# YT9215 register map
Vendor: Motorcomm; Series: YT921x; File version: 1.0
Registers are 32-bit, read-write, no defined reset value unless marked. A register's access mark holds for its fields unless they carry their own. Offsets are from the block's base; [hi:lo] are bit positions; lines under a group give offsets from that group; {n}, {i} and the like mark numbered series.

## PARSER — Ingress parser
Base 0x00210000
{0x0+4i} TPID_IGR[{i}] (i=0..3) — Four tag protocol identifier values the parser can recognise as a VLAN tag. PORT_IGR_TPID chooses which of them each port accepts. Index: n = 0 to 3.
  [15:0] TPID — Tag protocol identifier. An example is 0x8100.
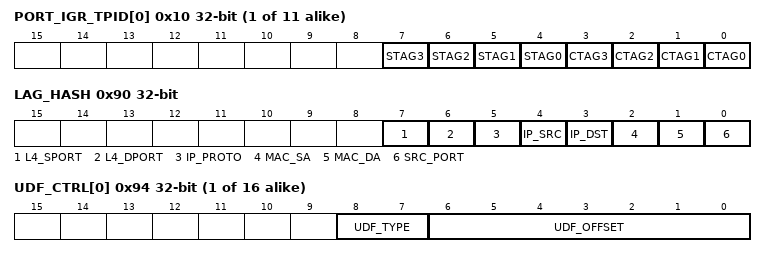
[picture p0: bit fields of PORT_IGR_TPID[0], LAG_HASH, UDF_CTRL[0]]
{0x10+4i} PORT_IGR_TPID[{i}] (i=0..10) — yt921x_vlan_aware_set writes the register to make a port VLAN-aware or VLAN-unaware. It is inferred from the names that the register chooses which TPID_IGR entries one port treats as a customer tag and which as a service tag. VLAN-aware and VLAN-unaware ports shows how this makes a port ignore VLAN tags. Index: port = 0 to 10.
  [n+4] STAG{n} (n=0..3) — It is inferred from the names that entry n of TPID_IGR marks a service tag on this port.
  [n] CTAG{n} (n=0..3) — It is inferred from the names that entry n of TPID_IGR marks a customer tag on this port.
0x90 LAG_HASH — Frame fields that feed the hash which spreads traffic over the members of a group.
  [7] L4_SPORT — Include the layer 4 source port.
  [6] L4_DPORT — Include the layer 4 destination port.
  [5] IP_PROTO — Include the IP protocol number.
  [4] IP_SRC — Include the IP source address.
  [3] IP_DST — Include the IP destination address.
  [2] MAC_SA — Include the source MAC address.
  [1] MAC_DA — Include the destination MAC address.
  [0] SRC_PORT — Include the receiving port.
{0x94+4i} UDF_CTRL[{i}] (i=0..15) — Position of one two-byte window that ACL keys of type UDF can match. Key type UDFk matches windows 2k and 2k + 1. Index: n = 0 to 15.
  [8:7] UDF_TYPE — Header the offset is counted from.
    0=L2 (Start of the Ethernet header); 1=L3 (Start of the layer 3 header); 2=L4 (Start of the layer 4 header)
  [6:0] UDF_OFFSET — Offset in bytes of the two-byte window from the start of that header.

## PORT_VLAN — Ingress port VLAN
Base 0x00230000
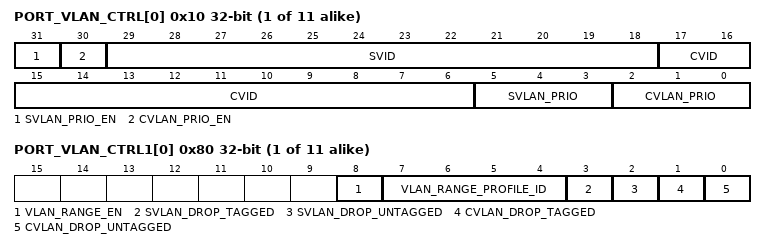
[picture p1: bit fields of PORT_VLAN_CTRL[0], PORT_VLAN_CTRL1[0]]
{0x10+4i} PORT_VLAN_CTRL[{i}] (i=0..10) — VLAN IDs and priorities given to frames that arrive on a port without the matching tag. Index: port = 0 to 10.
  [31] SVLAN_PRIO_EN — The Linux name reads as: use PORT_VLAN_CTRL.SVLAN_PRIO as the default service tag priority. The vendor SDK names the bit PRIORITY_TAG_SVID_EN, which reads as: give the default service VLAN ID to a priority-tagged frame. No code of either source uses the bit, and it is not known which reading is right.
  [30] CVLAN_PRIO_EN — The Linux name reads as: use PORT_VLAN_CTRL.CVLAN_PRIO as the default customer tag priority. The vendor SDK names the bit PRIORITY_TAG_CVID_EN, which reads as: give the default customer VLAN ID to a priority-tagged frame. No code of either source uses the bit, and it is not known which reading is right.
  [29:18] SVID — Default service VLAN ID.
  [17:6] CVID — Default customer VLAN ID (the port VLAN ID).
  [5:3] SVLAN_PRIO — Default service tag priority.
  [2:0] CVLAN_PRIO — Default customer tag priority.
{0x80+4i} PORT_VLAN_CTRL1[{i}] (i=0..10) — Drops tagged or untagged frames on receive, per tag kind. Index: port = 0 to 10.
  [8] VLAN_RANGE_EN — The Linux name reads as an enable of VLAN range matching with the profile in PORT_VLAN_CTRL1.VLAN_RANGE_PROFILE_ID. The vendor SDK names the bit VLAN_RANGE_MODE, and fal_tiger_vlan_trans_mode_set() writes a value of the list yt_vlan_range_trans_mode_t to it: 0 for the customer tag and 1 for the service tag. By that code the bit selects the tag that range matching uses, which disagrees with the Linux name. It is not known which is right.
  [7:4] VLAN_RANGE_PROFILE_ID — VLAN range profile number.
  [3] SVLAN_DROP_TAGGED — Drop received frames that carry a service tag.
  [2] SVLAN_DROP_UNTAGGED — Drop received frames that carry no service tag.
  [1] CVLAN_DROP_TAGGED — yt921x_vlan_filtering always clears the bit. It is inferred from the name that a set bit drops received frames that carry a customer tag.
  [0] CVLAN_DROP_UNTAGGED — Drop received frames that carry no customer tag.

## QUEUE — Queue manager
Base 0x00300000
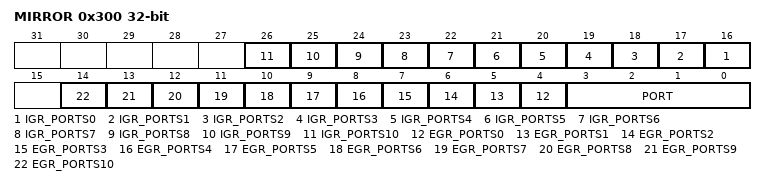
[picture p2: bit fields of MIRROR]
0x300 MIRROR — Source ports and the single monitor port of port mirroring.
  [n+16] IGR_PORTS{n} (n=0..10) — Ports whose received frames are copied to the monitor port. Each port has one bit.
  [n+4] EGR_PORTS{n} (n=0..10) — Ports whose sent frames are copied to the monitor port. Each port has one bit.
  [3:0] PORT — Monitor port number.

## SCHED — Egress scheduler
Base 0x00340000
0x0C PORT_SHAPE_SLOT — Period at which every port shaper adds tokens to its bucket.
  [11:0] SLOT — Slot length in units of eight core clock periods. SYS_CLK shows the core clock. The smallest allowed value is 80.
{0x14000+8i} PORT_SHAPE_CTRL[{i}] (i=0..10) group — 64-bit configuration of the single token bucket that limits what one port sends. Token arithmetic gives the conversion from bit rates. Index: port = 0 to 10.
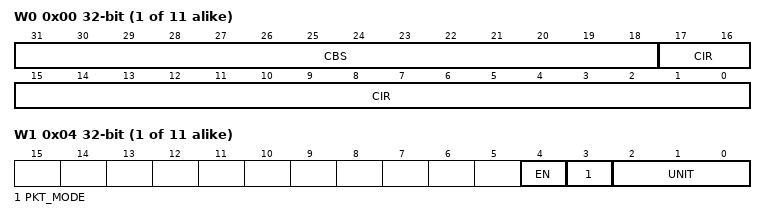
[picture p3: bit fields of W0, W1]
  0x00 W0 — Port egress shaper: bits 31 to 0. 64-bit configuration of the single token bucket that limits what one port sends. Token arithmetic gives the conversion from bit rates.
    [31:18] CBS — Burst size in tokens.
    [17:0] CIR — Rate in tokens per time slot.
  0x04 W1 — Port egress shaper: bits 63 to 32. 64-bit configuration of the single token bucket that limits what one port sends. Token arithmetic gives the conversion from bit rates.
    [4] EN — Enables the shaper.
    [3] PKT_MODE — Shape packets. Value 0 shapes bytes.
    [2:0] UNIT — Token scale. Every token value is multiplied by 4 to the power of this field.
{0x16000+4i} PORT_SHAPE_STAT[{i}] (i=0..10) ro — Current token count of one port shaper. The bit layout is not known. Index: port = 0 to 10.
  [31:0] VALUE — Layout not known.
